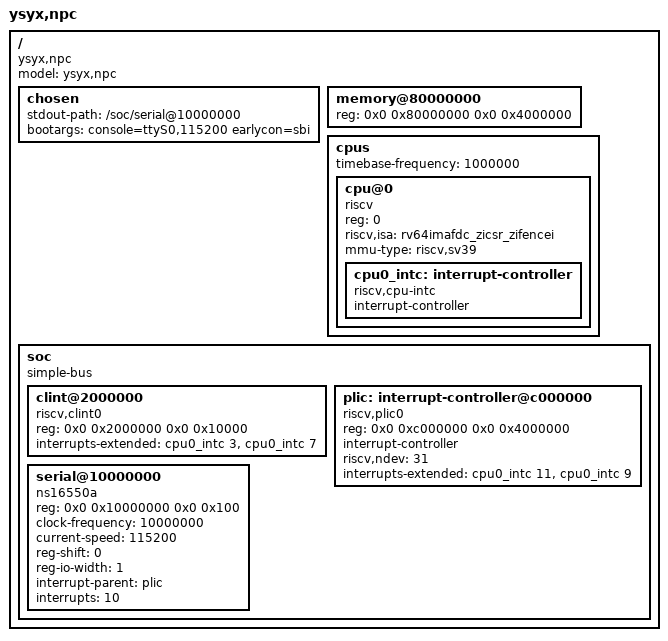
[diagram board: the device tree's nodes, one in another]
// SPDX-License-Identifier: GPL-2.0+
/*
 * ysyx-workbench NEMU RV64 的 U-Boot 开发用 DTS。
 *
 * 正常运行时不使用这份 DTB：板级 Kconfig 选择了 OF_HAS_PRIOR_STAGE，
 * OpenSBI 会把 nemu/scripts/build_linux_dtb.sh 生成的 DTB 放在
 * 0x83f00000 并通过 a1 传入。保留这份最小 DTS 只是为了让 U-Boot
 * 的 dt.dtb 构建目标有明确输入，并记录 NEMU 的固定设备地址。
 */

/dts-v1/;

/ {
	#address-cells = <2>;
	#size-cells = <2>;
	model = "ysyx,npc";
	compatible = "ysyx,npc";

	chosen {
		stdout-path = "/soc/serial@10000000";
		bootargs = "console=ttyS0,115200 earlycon=sbi";
	};

	memory@80000000 {
		device_type = "memory";
		reg = <0x0 0x80000000 0x0 0x4000000>;
	};

	cpus {
		#address-cells = <1>;
		#size-cells = <0>;
		timebase-frequency = <1000000>;

		cpu@0 {
			device_type = "cpu";
			compatible = "riscv";
			reg = <0>;
			status = "okay";
			riscv,isa = "rv64imafdc_zicsr_zifencei";
			mmu-type = "riscv,sv39";

			cpu0_intc: interrupt-controller {
				#interrupt-cells = <1>;
				compatible = "riscv,cpu-intc";
				interrupt-controller;
			};
		};
	};

	soc {
		#address-cells = <2>;
		#size-cells = <2>;
		compatible = "simple-bus";
		ranges;

		clint@2000000 {
			compatible = "riscv,clint0";
			reg = <0x0 0x2000000 0x0 0x10000>;
			interrupts-extended = <&cpu0_intc 3 &cpu0_intc 7>;
		};

		plic: interrupt-controller@c000000 {
			compatible = "riscv,plic0";
			reg = <0x0 0xc000000 0x0 0x4000000>;
			#interrupt-cells = <1>;
			interrupt-controller;
			riscv,ndev = <31>;
			interrupts-extended = <&cpu0_intc 11 &cpu0_intc 9>;
		};

		serial@10000000 {
			compatible = "ns16550a";
			reg = <0x0 0x10000000 0x0 0x100>;
			clock-frequency = <10000000>;
			current-speed = <115200>;
			reg-shift = <0>;
			reg-io-width = <1>;
			interrupt-parent = <&plic>;
			interrupts = <10>;
		};
	};
};
